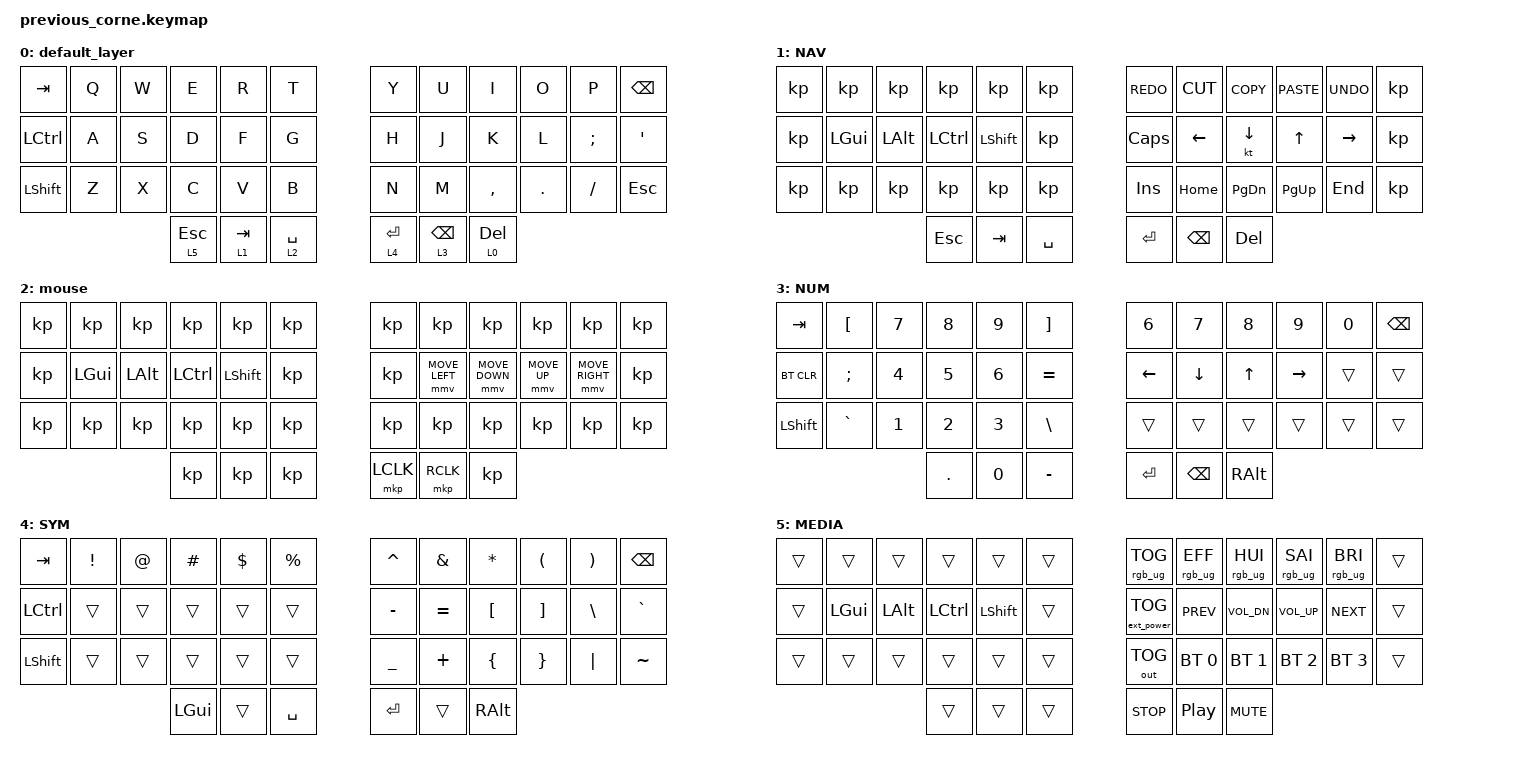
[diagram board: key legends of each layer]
    /*
 * Copyright (c) 2020 The ZMK Contributors
 *
 * SPDX-License-Identifier: MIT
 */

#include <behaviors.dtsi>
#include <dt-bindings/zmk/bt.h>
#include <dt-bindings/zmk/ext_power.h>
#include <dt-bindings/zmk/keys.h>
#include <dt-bindings/zmk/outputs.h>
#include <dt-bindings/zmk/pointing.h>
#include <dt-bindings/zmk/rgb.h>

/ {
    combos {
        compatible = "zmk,combos";

        CMD+A {
            bindings = <&kp LG(A)>;
            key-positions = <13 14>;
        };
    };

    keymap {
        compatible = "zmk,keymap";

        default_layer {
            // -----------------------------------------------------------------------------------------
            // |  TAB |  Q  |  W  |  E  |  R  |  T  |   |  Y  |  U   |  I  |  O  |  P  | BSPC |
            // | CTRL |  A  |  S  |  D  |  F  |  G  |   |  H  |  J   |  K  |  L  |  ;  |  '   |
            // | SHFT |  Z  |  X  |  C  |  V  |  B  |   |  N  |  M   |  ,  |  .  |  /  | ESC  |
            //                    | GUI | LWR | SPC |   | ENT | RSE  | ALT |

            bindings = <
&kp TAB    &kp Q  &kp W  &kp E         &kp R      &kp T          &kp Y         &kp U            &kp I         &kp O    &kp P     &kp BSPC
&kp LCTRL  &kp A  &kp S  &kp D         &kp F      &kp G          &kp H         &kp J            &kp K         &kp L    &kp SEMI  &kp SQT
&kp LSHFT  &kp Z  &kp X  &kp C         &kp V      &kp B          &kp N         &kp M            &kp COMMA     &kp DOT  &kp FSLH  &kp ESC
                         &lt 5 ESCAPE  &lt 1 TAB  &lt 2 SPACE    &lt 4 RETURN  &lt 3 BACKSPACE  &lt 0 DELETE
            >;
        };

        NAV {
            bindings = <
&kp  &kp       &kp       &kp         &kp        &kp          &kp K_REDO    &kp K_CUT      &kp K_COPY     &kp K_PASTE   &kp K_UNDO  &kp
&kp  &kp LGUI  &kp LALT  &kp LCTRL   &kp LSHFT  &kp          &kp CAPSLOCK  &kp LEFT       &kt DOWN       &kp UP_ARROW  &kp RIGHT   &kp
&kp  &kp       &kp       &kp         &kp        &kp          &kp INSERT    &kp HOME       &kp PAGE_DOWN  &kp PAGE_UP   &kp END     &kp
                         &kp ESCAPE  &kp TAB    &kp SPACE    &kp RETURN    &kp BACKSPACE  &kp DELETE
            >;
        };

        MOUSE {
            bindings = <
&kp  &kp           &kp           &kp        &kp             &kp    &kp        &kp             &kp  &kp  &kp  &kp
&kp  &kp LEFT_GUI  &kp LEFT_ALT  &kp LCTRL  &kp LEFT_SHIFT  &kp    &kp        &mmv MOVE_LEFT  &mmv MOVE_DOWN  &mmv MOVE_UP  &mmv MOVE_RIGHT  &kp
&kp  &kp           &kp           &kp        &kp             &kp    &kp        &kp             &kp  &kp  &kp  &kp
                                 &kp        &kp             &kp    &mkp LCLK  &mkp RCLK       &kp
            >;

            label = "mouse";
        };

        NUM {
            // -----------------------------------------------------------------------------------------
            // |  TAB |  1  |  2  |  3  |  4  |  5  |   |  6  |  7  |  8  |  9  |  0  | BSPC |
            // | BTCLR| BT1 | BT2 | BT3 | BT4 | BT5 |   | LFT | DWN |  UP | RGT |     |      |
            // | SHFT |     |     |     |     |     |   |     |     |     |     |     |      |
            //                    | GUI |     | SPC |   | ENT |     | ALT |

            bindings = <
&kp TAB     &kp LBKT   &kp N7  &kp N8   &kp N9  &kp RBKT     &kp N6    &kp N7    &kp N8    &kp N9     &kp N0  &kp BSPC
&bt BT_CLR  &kp SEMI   &kp N4  &kp N5   &kp N6  &kp EQUAL    &kp LEFT  &kp DOWN  &kp UP    &kp RIGHT  &trans  &trans
&kp LSHFT   &kp GRAVE  &kp N1  &kp N2   &kp N3  &kp BSLH     &trans    &trans    &trans    &trans     &trans  &trans
                               &kp DOT  &kp N0  &kp MINUS    &kp RET   &kp BSPC  &kp RALT
            >;
        };

        SYM {
            // -----------------------------------------------------------------------------------------
            // |  TAB |  !  |  @  |  #  |  $  |  %  |   |  ^  |  &  |  *  |  (  |  )  | BSPC |
            // | CTRL |     |     |     |     |     |   |  -  |  =  |  [  |  ]  |  \  |  `   |
            // | SHFT |     |     |     |     |     |   |  _  |  +  |  {  |  }  | "|" |  ~   |
            //                    | GUI |     | SPC |   | ENT |     | ALT |

            bindings = <
&kp TAB    &kp EXCL  &kp AT  &kp HASH  &kp DLLR  &kp PRCNT    &kp CARET  &kp AMPS   &kp ASTRK  &kp LPAR  &kp RPAR  &kp BSPC
&kp LCTRL  &trans    &trans  &trans    &trans    &trans       &kp MINUS  &kp EQUAL  &kp LBKT   &kp RBKT  &kp BSLH  &kp GRAVE
&kp LSHFT  &trans    &trans  &trans    &trans    &trans       &kp UNDER  &kp PLUS   &kp LBRC   &kp RBRC  &kp PIPE  &kp TILDE
                             &kp LGUI  &trans    &kp SPACE    &kp RET    &trans     &kp RALT
            >;
        };

        MEDIA {
            bindings = <
&trans    &trans    &trans    &trans    &trans    &trans      &rgb_ug RGB_TOG    &rgb_ug RGB_EFF  &rgb_ug RGB_HUI  &rgb_ug RGB_SAI  &rgb_ug RGB_BRI  &trans
&trans    &kp LGUI  &kp LALT  &kp LCTRL &kp LSHFT &trans      &ext_power EP_TOG  &kp C_PREV       &kp C_VOL_DN     &kp C_VOL_UP   &kp C_NEXT   &trans    
&trans    &trans    &trans    &trans    &trans    &trans      &out OUT_TOG       &bt BT_SEL 0     &bt BT_SEL 1     &bt BT_SEL 2   &bt BT_SEL 3   &trans    
                               &trans    &trans    &trans      &kp C_STOP         &kp C_PP         &kp C_MUTE
            >;
        };
    };
};
